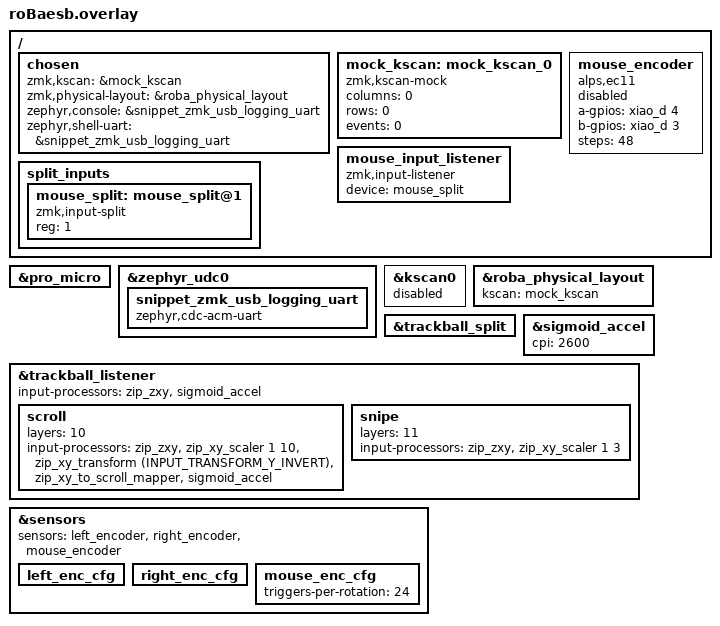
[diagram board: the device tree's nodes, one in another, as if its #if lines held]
/* Alias xiao_d to pro_micro so roBa.dtsi resolves on any board with a
 * pro_micro connector. All nodes that reference xiao_d (kscan0, encoders)
 * are disabled below. */
xiao_d: &pro_micro {};

#include "../roBa/roBa.dtsi"
#include "roBaesb_addr.dtsi"
#include <input/processors/xyz.dtsi>
#include <behaviors/input_processor_sigmoid_accel.dtsi>

#ifdef ZMK_ESB_MOUSE
#include "roBaesb_lariska_transform.dtsi"
#endif

/ {
    chosen {
        zmk,kscan = &mock_kscan;
        zmk,physical-layout = &roba_physical_layout;
        zephyr,console = &snippet_zmk_usb_logging_uart;
        zephyr,shell-uart = &snippet_zmk_usb_logging_uart;
    };

    mock_kscan: mock_kscan_0 {
        compatible = "zmk,kscan-mock";
        columns = <0>;
        rows = <0>;
        events = <0>;
    };

#ifdef ZMK_ESB_MOUSE
    mouse_encoder: mouse_encoder {
        compatible = "alps,ec11";
        a-gpios = <&xiao_d 4 (GPIO_ACTIVE_HIGH | GPIO_PULL_UP)>;
        b-gpios = <&xiao_d 3 (GPIO_ACTIVE_HIGH | GPIO_PULL_UP)>;
        steps = <48>;
        status = "disabled";
    };

    split_inputs {
        mouse_split: mouse_split@1 {
            compatible = "zmk,input-split";
            reg = <1>;
            status = "okay";
        };
    };

    mouse_input_listener: mouse_input_listener {
        compatible = "zmk,input-listener";
        status = "okay";
        device = <&mouse_split>;
    };
#endif
};

&zephyr_udc0 {
    snippet_zmk_usb_logging_uart: snippet_zmk_usb_logging_uart {
        compatible = "zephyr,cdc-acm-uart";
    };
};

&kscan0 {
    status = "disabled";
};

&roba_physical_layout {
    kscan = <&mock_kscan>;
};

&trackball_split {
    status = "okay";
};

&sigmoid_accel {
    cpi = <2600>;
};

/* sigmoid_accel applied ONLY to the roBa right-side trackball listener. */
&trackball_listener {
    status = "okay";
    input-processors = <&zip_zxy>, <&sigmoid_accel>;

    scroll {
        layers = <10>;
        input-processors = <&zip_zxy>, <&zip_xy_scaler 1 10>, <&zip_xy_transform (INPUT_TRANSFORM_Y_INVERT)>, <&zip_xy_to_scroll_mapper>, <&sigmoid_accel>;
    };

    snipe {
        layers = <11>;
        input-processors = <&zip_zxy>, <&zip_xy_scaler 1 3>;
    };
};

#ifdef ZMK_ESB_MOUSE
&sensors {
    sensors = <&left_encoder &right_encoder &mouse_encoder>;
    left_enc_cfg: left_enc_cfg {};
    right_enc_cfg: right_enc_cfg {};
    mouse_enc_cfg: mouse_enc_cfg {
        triggers-per-rotation = <24>;
    };
};
#endif
